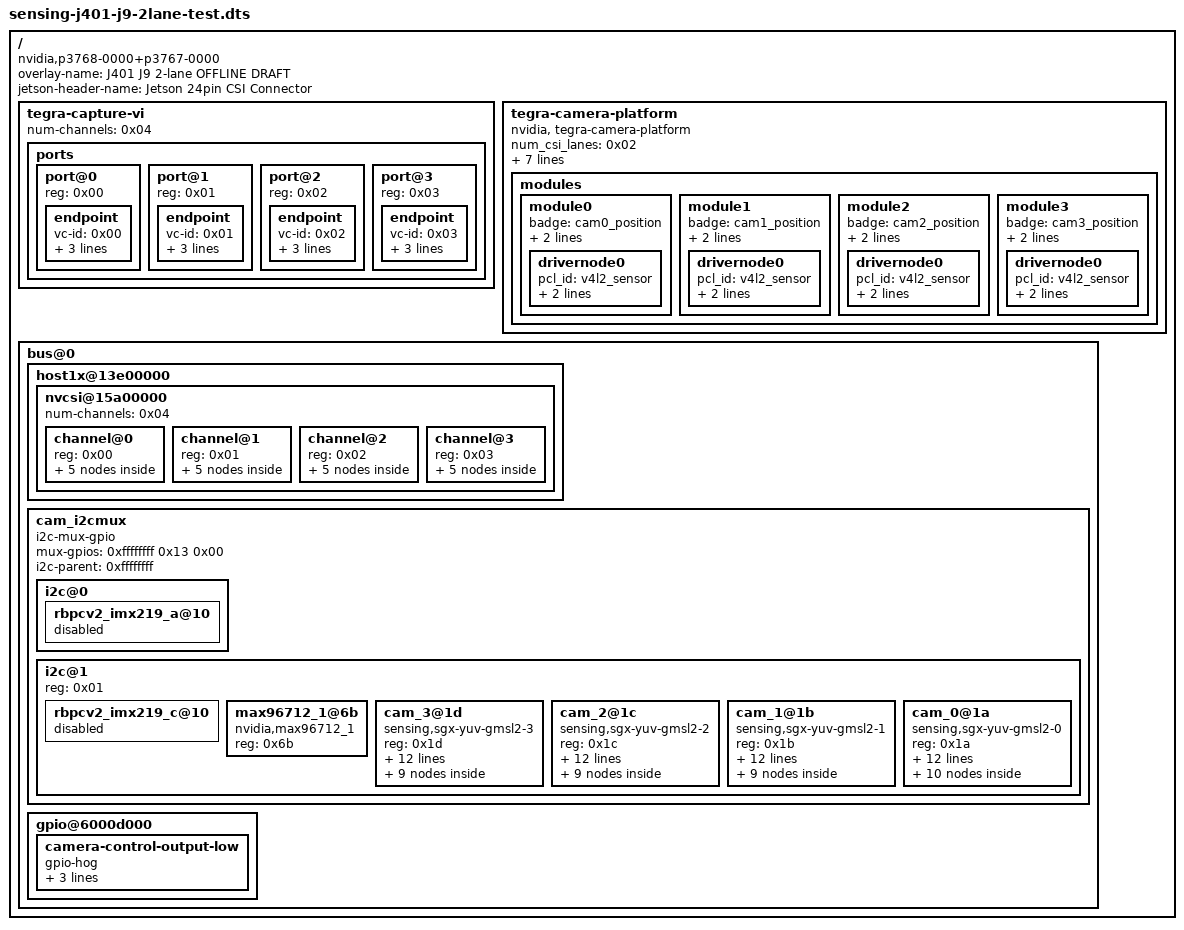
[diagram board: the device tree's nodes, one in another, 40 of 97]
/dts-v1/;

/ {
	overlay-name = "J401 J9 2-lane OFFLINE DRAFT";
	jetson-header-name = "Jetson 24pin CSI Connector";
	compatible = "nvidia,p3768-0000+p3767-0000\0nvidia,p3768-0000+p3767-0001\0nvidia,p3768-0000+p3767-0003\0nvidia,p3768-0000+p3767-0004\0nvidia,p3768-0000+p3767-0005\0nvidia,p3768-0000+p3767-0000-super\0nvidia,p3768-0000+p3767-0001-super\0nvidia,p3768-0000+p3767-0003-super\0nvidia,p3768-0000+p3767-0004-super\0nvidia,p3768-0000+p3767-0005-super";

	fragment@0 {
		target-path = "/";

		__overlay__ {

			tegra-capture-vi {
				num-channels = <0x04>;

				ports {
					#address-cells = <0x01>;
					#size-cells = <0x00>;

					port@0 {
						reg = <0x00>;

						endpoint {
							vc-id = <0x00>;
							port-index = <0x02>;
							bus-width = <0x02>;
							remote-endpoint = <0x01>;
							phandle = <0x06>;
						};
					};

					port@1 {
						reg = <0x01>;

						endpoint {
							vc-id = <0x01>;
							port-index = <0x02>;
							bus-width = <0x02>;
							remote-endpoint = <0x02>;
							phandle = <0x08>;
						};
					};

					port@2 {
						reg = <0x02>;

						endpoint {
							vc-id = <0x02>;
							port-index = <0x02>;
							bus-width = <0x02>;
							remote-endpoint = <0x03>;
							phandle = <0x0a>;
						};
					};

					port@3 {
						reg = <0x03>;

						endpoint {
							vc-id = <0x03>;
							port-index = <0x02>;
							bus-width = <0x02>;
							remote-endpoint = <0x04>;
							phandle = <0x0c>;
						};
					};
				};
			};

			tegra-camera-platform {
				compatible = "nvidia, tegra-camera-platform";
				num_csi_lanes = <0x02>;
				max_lane_speed = <0x16e360>;
				min_bits_per_pixel = <0x0a>;
				vi_peak_byte_per_pixel = <0x02>;
				vi_bw_margin_pct = <0x19>;
				max_pixel_rate = <0x7270e0>;
				isp_peak_byte_per_pixel = <0x05>;
				isp_bw_margin_pct = <0x19>;

				modules {

					module0 {
						badge = "cam0_position";
						position = "position";
						orientation = "1";

						drivernode0 {
							pcl_id = "v4l2_sensor";
							sysfs-device-tree = "/sys/firmware/devicetree/base/bus@0/cam_i2cmux/i2c@1/cam_0@1a";
						};
					};

					module1 {
						badge = "cam1_position";
						position = "position";
						orientation = "1";

						drivernode0 {
							pcl_id = "v4l2_sensor";
							sysfs-device-tree = "/sys/firmware/devicetree/base/bus@0/cam_i2cmux/i2c@1/cam_1@1b";
						};
					};

					module2 {
						badge = "cam2_position";
						position = "position";
						orientation = "1";

						drivernode0 {
							pcl_id = "v4l2_sensor";
							sysfs-device-tree = "/sys/firmware/devicetree/base/bus@0/cam_i2cmux/i2c@1/cam_2@1c";
						};
					};

					module3 {
						badge = "cam3_position";
						position = "position";
						orientation = "1";

						drivernode0 {
							pcl_id = "v4l2_sensor";
							sysfs-device-tree = "/sys/firmware/devicetree/base/bus@0/cam_i2cmux/i2c@1/cam_3@1d";
						};
					};
				};
			};

			bus@0 {

				host1x@13e00000 {

					nvcsi@15a00000 {
						num-channels = <0x04>;
						#address-cells = <0x01>;
						#size-cells = <0x00>;

						channel@0 {
							reg = <0x00>;

							ports {
								#address-cells = <0x01>;
								#size-cells = <0x00>;

								port@0 {
									reg = <0x00>;

									endpoint@0 {
										port-index = <0x02>;
										bus-width = <0x02>;
										remote-endpoint = <0x05>;
										phandle = <0x10>;
									};
								};

								port@1 {
									reg = <0x01>;

									endpoint@1 {
										remote-endpoint = <0x06>;
										phandle = <0x01>;
									};
								};
							};
						};

						channel@1 {
							reg = <0x01>;

							ports {
								#address-cells = <0x01>;
								#size-cells = <0x00>;

								port@0 {
									reg = <0x00>;

									endpoint@2 {
										port-index = <0x02>;
										bus-width = <0x02>;
										remote-endpoint = <0x07>;
										phandle = <0x0f>;
									};
								};

								port@1 {
									reg = <0x01>;

									endpoint@3 {
										remote-endpoint = <0x08>;
										phandle = <0x02>;
									};
								};
							};
						};

						channel@2 {
							reg = <0x02>;

							ports {
								#address-cells = <0x01>;
								#size-cells = <0x00>;

								port@0 {
									reg = <0x00>;

									endpoint@4 {
										port-index = <0x02>;
										bus-width = <0x02>;
										remote-endpoint = <0x09>;
										phandle = <0x0e>;
									};
								};

								port@1 {
									reg = <0x01>;

									endpoint@5 {
										remote-endpoint = <0x0a>;
										phandle = <0x03>;
									};
								};
							};
						};

						channel@3 {
							reg = <0x03>;

							ports {
								#address-cells = <0x01>;
								#size-cells = <0x00>;

								port@0 {
									reg = <0x00>;

									endpoint@6 {
										port-index = <0x02>;
										bus-width = <0x02>;
										remote-endpoint = <0x0b>;
										phandle = <0x0d>;
									};
								};

								port@1 {
									reg = <0x01>;

									endpoint@7 {
										remote-endpoint = <0x0c>;
										phandle = <0x04>;
									};
								};
							};
						};
					};
				};

				cam_i2cmux {
					status = "okay";
					compatible = "i2c-mux-gpio";
					#address-cells = <0x01>;
					#size-cells = <0x00>;
					mux-gpios = <0xffffffff 0x13 0x00>;
					i2c-parent = <0xffffffff>;

					i2c@0 {

						rbpcv2_imx219_a@10 {
							status = "disabled";
						};
					};

					i2c@1 {
						status = "okay";
						reg = <0x01>;
						#address-cells = <0x01>;
						#size-cells = <0x00>;

						rbpcv2_imx219_c@10 {
							status = "disabled";
						};

						max96712_1@6b {
							status = "okay";
							compatible = "nvidia,max96712_1";
							reg = <0x6b>;
						};

						cam_3@1d {
							status = "okay";
							compatible = "sensing,sgx-yuv-gmsl2-3";
							reg = <0x1d>;
							def_addr = <0x34>;
							devnode = "video3";
							physical_w = "15.0";
							physical_h = "12.5";
							sensor_model = "sgx-yuv-gmsl2";
							post_crop_frame_drop = "0";
							use_decibel_gain = "false";
							use_sensor_mode_id = "true";
							clocks = <0xffffffff 0x24 0xffffffff 0x24>;
							clock-names = "extperiph1\0pllp_grtba";
							mclk = "extperiph1";
							der_id = <0x01>;
							reset-gpios = <0xffffffff 0xa0 0x00>;

							mode0 {
								mclk_khz = "24000";
								num_lanes = "2";
								tegra_sinterface = "serial_c";
								vc_id = "3";
								discontinuous_clk = "no";
								dpcm_enable = "false";
								cil_settletime = "0";
								dynamic_pixel_bit_depth = "16";
								csi_pixel_bit_depth = "16";
								mode_type = "yuv";
								pixel_phase = "uyvy";
								active_w = "1920";
								active_h = "1080";
								readout_orientation = "0";
								line_length = "2200";
								inherent_gain = "1";
								pix_clk_hz = "150000000";
								serdes_pix_clk_hz = "350000000";
								gain_factor = "16";
								min_gain_val = "16";
								max_gain_val = "356";
								step_gain_val = "1";
								default_gain = "16";
								min_hdr_ratio = "1";
								max_hdr_ratio = "1";
								framerate_factor = "1000000";
								min_framerate = "30000000";
								max_framerate = "30000000";
								step_framerate = "1";
								default_framerate = "30000000";
								exposure_factor = "1000000";
								min_exp_time = "59";
								max_exp_time = "33333";
								step_exp_time = "1";
								default_exp_time = "33333";
								embedded_metadata_height = "0";
							};

							mode1 {
								mclk_khz = "24000";
								num_lanes = "2";
								tegra_sinterface = "serial_c";
								vc_id = "3";
								discontinuous_clk = "no";
								dpcm_enable = "false";
								cil_settletime = "0";
								dynamic_pixel_bit_depth = "16";
								csi_pixel_bit_depth = "16";
								mode_type = "yuv";
								pixel_phase = "uyvy";
								active_w = "1920";
								active_h = "1536";
								readout_orientation = "0";
								line_length = "2200";
								inherent_gain = "1";
								pix_clk_hz = "200000000";
								serdes_pix_clk_hz = "350000000";
								gain_factor = "16";
								min_gain_val = "16";
								max_gain_val = "356";
								step_gain_val = "1";
								default_gain = "16";
								min_hdr_ratio = "1";
								max_hdr_ratio = "1";
								framerate_factor = "1000000";
								min_framerate = "30000000";
								max_framerate = "30000000";
								step_framerate = "1";
								default_framerate = "30000000";
								exposure_factor = "1000000";
								min_exp_time = "28";
								max_exp_time = "22000";
								step_exp_time = "1";
								default_exp_time = "22000";
								embedded_metadata_height = "0";
							};

							mode2 {
								mclk_khz = "24000";
								num_lanes = "2";
								tegra_sinterface = "serial_c";
								vc_id = "3";
								discontinuous_clk = "no";
								dpcm_enable = "false";
								cil_settletime = "0";
								dynamic_pixel_bit_depth = "16";
								csi_pixel_bit_depth = "16";
								mode_type = "yuv";
								pixel_phase = "uyvy";
								active_w = "2880";
								active_h = "1860";
								readout_orientation = "0";
								line_length = "3200";
								inherent_gain = "1";
								pix_clk_hz = "214300000";
								serdes_pix_clk_hz = "350000000";
								gain_factor = "16";
								min_gain_val = "16";
								max_gain_val = "356";
								step_gain_val = "1";
								default_gain = "16";
								min_hdr_ratio = "1";
								max_hdr_ratio = "1";
								framerate_factor = "1000000";
								min_framerate = "30000000";
								max_framerate = "30000000";
								step_framerate = "1";
								default_framerate = "30000000";
								exposure_factor = "1000000";
								min_exp_time = "59";
								max_exp_time = "33333";
								step_exp_time = "1";
								default_exp_time = "33333";
								embedded_metadata_height = "0";
							};

							mode3 {
								mclk_khz = "24000";
								num_lanes = "2";
								tegra_sinterface = "serial_c";
								vc_id = "3";
								discontinuous_clk = "no";
								dpcm_enable = "false";
								cil_settletime = "0";
								dynamic_pixel_bit_depth = "16";
								csi_pixel_bit_depth = "16";
								mode_type = "yuv";
								pixel_phase = "uyvy";
								active_w = "3840";
								active_h = "2160";
								readout_orientation = "0";
								line_length = "4200";
								inherent_gain = "1";
								pix_clk_hz = "150000000";
								serdes_pix_clk_hz = "350000000";
								gain_factor = "16";
								min_gain_val = "16";
								max_gain_val = "356";
								step_gain_val = "1";
								default_gain = "16";
								min_hdr_ratio = "1";
								max_hdr_ratio = "1";
								framerate_factor = "1000000";
								min_framerate = "30000000";
								max_framerate = "30000000";
								step_framerate = "1";
								default_framerate = "30000000";
								exposure_factor = "1000000";
								min_exp_time = "59";
								max_exp_time = "33333";
								step_exp_time = "1";
								default_exp_time = "33333";
								embedded_metadata_height = "0";
							};

							mode4 {
								mclk_khz = "24000";
								num_lanes = "2";
								tegra_sinterface = "serial_c";
								vc_id = "3";
								discontinuous_clk = "no";
								dpcm_enable = "false";
								cil_settletime = "0";
								dynamic_pixel_bit_depth = "16";
								csi_pixel_bit_depth = "16";
								mode_type = "yuv";
								pixel_phase = "uyvy";
								active_w = "1280";
								active_h = "720";
								readout_orientation = "0";
								line_length = "2200";
								inherent_gain = "1";
								pix_clk_hz = "150000000";
								serdes_pix_clk_hz = "350000000";
								gain_factor = "16";
								min_gain_val = "16";
								max_gain_val = "356";
								step_gain_val = "1";
								default_gain = "16";
								min_hdr_ratio = "1";
								max_hdr_ratio = "1";
								framerate_factor = "1000000";
								min_framerate = "30000000";
								max_framerate = "30000000";
								step_framerate = "1";
								default_framerate = "30000000";
								exposure_factor = "1000000";
								min_exp_time = "59";
								max_exp_time = "33333";
								step_exp_time = "1";
								default_exp_time = "33333";
								embedded_metadata_height = "0";
							};

							mode5 {
								mclk_khz = "24000";
								num_lanes = "2";
								tegra_sinterface = "serial_c";
								vc_id = "3";
								discontinuous_clk = "no";
								dpcm_enable = "false";
								cil_settletime = "0";
								dynamic_pixel_bit_depth = "16";
								csi_pixel_bit_depth = "16";
								mode_type = "yuv";
								pixel_phase = "uyvy";
								active_w = "3840";
								active_h = "2160";
								readout_orientation = "0";
								line_length = "2200";
								inherent_gain = "1";
								pix_clk_hz = "150000000";
								serdes_pix_clk_hz = "350000000";
								gain_factor = "16";
								min_gain_val = "16";
								max_gain_val = "356";
								step_gain_val = "1";
								default_gain = "16";
								min_hdr_ratio = "1";
								max_hdr_ratio = "1";
								framerate_factor = "1000000";
								min_framerate = "30000000";
								max_framerate = "30000000";
								step_framerate = "1";
								default_framerate = "30000000";
								exposure_factor = "1000000";
								min_exp_time = "59";
								max_exp_time = "33333";
								step_exp_time = "1";
								default_exp_time = "33333";
								embedded_metadata_height = "0";
							};

							ports {
								#address-cells = <0x01>;
								#size-cells = <0x00>;

								port@0 {
									reg = <0x00>;

									endpoint {
										vc-id = <0x03>;
										port-index = <0x02>;
										bus-width = <0x02>;
										remote-endpoint = <0x0d>;
										phandle = <0x0b>;
									};
								};
							};
						};

						cam_2@1c {
							status = "okay";
							compatible = "sensing,sgx-yuv-gmsl2-2";
							reg = <0x1c>;
							def_addr = <0x34>;
							devnode = "video2";
							physical_w = "15.0";
							physical_h = "12.5";
							sensor_model = "sgx-yuv-gmsl2";
							post_crop_frame_drop = "0";
							use_decibel_gain = "false";
							use_sensor_mode_id = "true";
							clocks = <0xffffffff 0x24 0xffffffff 0x24>;
							clock-names = "extperiph1\0pllp_grtba";
							mclk = "extperiph1";
							der_id = <0x01>;
							reset-gpios = <0xffffffff 0xa0 0x00>;

							mode0 {
								mclk_khz = "24000";
								num_lanes = "2";
								tegra_sinterface = "serial_c";
								vc_id = "2";
								discontinuous_clk = "no";
								dpcm_enable = "false";
								cil_settletime = "0";
								dynamic_pixel_bit_depth = "16";
								csi_pixel_bit_depth = "16";
								mode_type = "yuv";
								pixel_phase = "uyvy";
								active_w = "1920";
								active_h = "1080";
								readout_orientation = "0";
								line_length = "2200";
								inherent_gain = "1";
								pix_clk_hz = "150000000";
								serdes_pix_clk_hz = "350000000";
								gain_factor = "16";
								min_gain_val = "16";
								max_gain_val = "356";
								step_gain_val = "1";
								default_gain = "16";
								min_hdr_ratio = "1";
								max_hdr_ratio = "1";
								framerate_factor = "1000000";
								min_framerate = "30000000";
								max_framerate = "30000000";
								step_framerate = "1";
								default_framerate = "30000000";
								exposure_factor = "1000000";
								min_exp_time = "59";
								max_exp_time = "33333";
								step_exp_time = "1";
								default_exp_time = "33333";
								embedded_metadata_height = "0";
							};

							mode1 {
								mclk_khz = "24000";
								num_lanes = "2";
								tegra_sinterface = "serial_c";
								vc_id = "2";
								discontinuous_clk = "no";
								dpcm_enable = "false";
								cil_settletime = "0";
								dynamic_pixel_bit_depth = "16";
								csi_pixel_bit_depth = "16";
								mode_type = "yuv";
								pixel_phase = "uyvy";
								active_w = "1920";
								active_h = "1536";
								readout_orientation = "0";
								line_length = "2200";
								inherent_gain = "1";
								pix_clk_hz = "200000000";
								serdes_pix_clk_hz = "350000000";
								gain_factor = "16";
								min_gain_val = "16";
								max_gain_val = "356";
								step_gain_val = "1";
								default_gain = "16";
								min_hdr_ratio = "1";
								max_hdr_ratio = "1";
								framerate_factor = "1000000";
								min_framerate = "30000000";
								max_framerate = "30000000";
								step_framerate = "1";
								default_framerate = "30000000";
								exposure_factor = "1000000";
								min_exp_time = "28";
								max_exp_time = "22000";
								step_exp_time = "1";
								default_exp_time = "22000";
								embedded_metadata_height = "0";
							};

							mode2 {
								mclk_khz = "24000";
								num_lanes = "2";
								tegra_sinterface = "serial_c";
								vc_id = "2";
								discontinuous_clk = "no";
								dpcm_enable = "false";
								cil_settletime = "0";
								dynamic_pixel_bit_depth = "16";
								csi_pixel_bit_depth = "16";
								mode_type = "yuv";
								pixel_phase = "uyvy";
								active_w = "2880";
								active_h = "1860";
								readout_orientation = "0";
								line_length = "3200";
								inherent_gain = "1";
								pix_clk_hz = "214300000";
								serdes_pix_clk_hz = "350000000";
								gain_factor = "16";
								min_gain_val = "16";
								max_gain_val = "356";
								step_gain_val = "1";
								default_gain = "16";
								min_hdr_ratio = "1";
								max_hdr_ratio = "1";
								framerate_factor = "1000000";
								min_framerate = "30000000";
								max_framerate = "30000000";
								step_framerate = "1";
								default_framerate = "30000000";
								exposure_factor = "1000000";
								min_exp_time = "59";
								max_exp_time = "33333";
								step_exp_time = "1";
								default_exp_time = "33333";
								embedded_metadata_height = "0";
							};

							mode3 {
								mclk_khz = "24000";
								num_lanes = "2";
								tegra_sinterface = "serial_c";
								vc_id = "2";
								discontinuous_clk = "no";
								dpcm_enable = "false";
								cil_settletime = "0";
								dynamic_pixel_bit_depth = "16";
								csi_pixel_bit_depth = "16";
								mode_type = "yuv";
								pixel_phase = "uyvy";
								active_w = "3840";
								active_h = "2160";
								readout_orientation = "0";
								line_length = "4200";
								inherent_gain = "1";
								pix_clk_hz = "150000000";
								serdes_pix_clk_hz = "350000000";
								gain_factor = "16";
								min_gain_val = "16";
								max_gain_val = "356";
								step_gain_val = "1";
								default_gain = "16";
								min_hdr_ratio = "1";
								max_hdr_ratio = "1";
								framerate_factor = "1000000";
								min_framerate = "30000000";
								max_framerate = "30000000";
								step_framerate = "1";
								default_framerate = "30000000";
								exposure_factor = "1000000";
								min_exp_time = "59";
								max_exp_time = "33333";
								step_exp_time = "1";
								default_exp_time = "33333";
								embedded_metadata_height = "0";
							};

							mode4 {
								mclk_khz = "24000";
								num_lanes = "2";
								tegra_sinterface = "serial_c";
								vc_id = "2";
								discontinuous_clk = "no";
								dpcm_enable = "false";
								cil_settletime = "0";
								dynamic_pixel_bit_depth = "16";
								csi_pixel_bit_depth = "16";
								mode_type = "yuv";
								pixel_phase = "uyvy";
								active_w = "1280";
								active_h = "720";
								readout_orientation = "0";
								line_length = "2200";
								inherent_gain = "1";
								pix_clk_hz = "150000000";
								serdes_pix_clk_hz = "350000000";
								gain_factor = "16";
								min_gain_val = "16";
								max_gain_val = "356";
								step_gain_val = "1";
								default_gain = "16";
								min_hdr_ratio = "1";
								max_hdr_ratio = "1";
								framerate_factor = "1000000";
								min_framerate = "30000000";
								max_framerate = "30000000";
								step_framerate = "1";
								default_framerate = "30000000";
								exposure_factor = "1000000";
								min_exp_time = "59";
								max_exp_time = "33333";
								step_exp_time = "1";
								default_exp_time = "33333";
								embedded_metadata_height = "0";
							};

							mode5 {
								mclk_khz = "24000";
								num_lanes = "2";
								tegra_sinterface = "serial_c";
								vc_id = "2";
								discontinuous_clk = "no";
								dpcm_enable = "false";
								cil_settletime = "0";
								dynamic_pixel_bit_depth = "16";
								csi_pixel_bit_depth = "16";
								mode_type = "yuv";
								pixel_phase = "uyvy";
								active_w = "3840";
								active_h = "2160";
								readout_orientation = "0";
								line_length = "2200";
								inherent_gain = "1";
								pix_clk_hz = "150000000";
								serdes_pix_clk_hz = "350000000";
								gain_factor = "16";
								min_gain_val = "16";
								max_gain_val = "356";
								step_gain_val = "1";
								default_gain = "16";
								min_hdr_ratio = "1";
								max_hdr_ratio = "1";
								framerate_factor = "1000000";
								min_framerate = "30000000";
								max_framerate = "30000000";
								step_framerate = "1";
								default_framerate = "30000000";
								exposure_factor = "1000000";
								min_exp_time = "59";
								max_exp_time = "33333";
								step_exp_time = "1";
								default_exp_time = "33333";
								embedded_metadata_height = "0";
							};

							ports {
								#address-cells = <0x01>;
								#size-cells = <0x00>;

								port@0 {
									reg = <0x00>;

									endpoint {
										vc-id = <0x02>;
										port-index = <0x02>;
										bus-width = <0x02>;
										remote-endpoint = <0x0e>;
										phandle = <0x09>;
									};
								};
							};
						};

						cam_1@1b {
							status = "okay";
							compatible = "sensing,sgx-yuv-gmsl2-1";
							reg = <0x1b>;
							def_addr = <0x34>;
							devnode = "video1";
							physical_w = "15.0";
							physical_h = "12.5";
							sensor_model = "sgx-yuv-gmsl2";
							post_crop_frame_drop = "0";
							use_decibel_gain = "false";
							use_sensor_mode_id = "true";
							clocks = <0xffffffff 0x24 0xffffffff 0x24>;
							clock-names = "extperiph1\0pllp_grtba";
							mclk = "extperiph1";
							der_id = <0x01>;
							reset-gpios = <0xffffffff 0xa0 0x00>;

							mode0 {
								mclk_khz = "24000";
								num_lanes = "2";
								tegra_sinterface = "serial_c";
								vc_id = "1";
								discontinuous_clk = "no";
								dpcm_enable = "false";
								cil_settletime = "0";
								dynamic_pixel_bit_depth = "16";
								csi_pixel_bit_depth = "16";
								mode_type = "yuv";
								pixel_phase = "uyvy";
								active_w = "1920";
								active_h = "1080";
								readout_orientation = "0";
								line_length = "2200";
								inherent_gain = "1";
								pix_clk_hz = "150000000";
								serdes_pix_clk_hz = "350000000";
								gain_factor = "16";
								min_gain_val = "16";
								max_gain_val = "356";
								step_gain_val = "1";
								default_gain = "16";
								min_hdr_ratio = "1";
								max_hdr_ratio = "1";
								framerate_factor = "1000000";
								min_framerate = "30000000";
								max_framerate = "30000000";
								step_framerate = "1";
								default_framerate = "30000000";
								exposure_factor = "1000000";
								min_exp_time = "59";
								max_exp_time = "33333";
								step_exp_time = "1";
								default_exp_time = "33333";
								embedded_metadata_height = "0";
							};

							mode1 {
								mclk_khz = "24000";
								num_lanes = "2";
								tegra_sinterface = "serial_c";
								vc_id = "1";
								discontinuous_clk = "no";
								dpcm_enable = "false";
								cil_settletime = "0";
								dynamic_pixel_bit_depth = "16";
								csi_pixel_bit_depth = "16";
								mode_type = "yuv";
								pixel_phase = "uyvy";
								active_w = "1920";
								active_h = "1536";
								readout_orientation = "0";
								line_length = "2200";
								inherent_gain = "1";
								pix_clk_hz = "200000000";
								serdes_pix_clk_hz = "350000000";
								gain_factor = "16";
								min_gain_val = "16";
								max_gain_val = "356";
								step_gain_val = "1";
								default_gain = "16";
								min_hdr_ratio = "1";
								max_hdr_ratio = "1";
								framerate_factor = "1000000";
								min_framerate = "30000000";
								max_framerate = "30000000";
								step_framerate = "1";
								default_framerate = "30000000";
								exposure_factor = "1000000";
								min_exp_time = "28";
								max_exp_time = "22000";
								step_exp_time = "1";
								default_exp_time = "22000";
								embedded_metadata_height = "0";
							};

							mode2 {
								mclk_khz = "24000";
								num_lanes = "2";
								tegra_sinterface = "serial_c";
								vc_id = "1";
								discontinuous_clk = "no";
								dpcm_enable = "false";
								cil_settletime = "0";
								dynamic_pixel_bit_depth = "16";
								csi_pixel_bit_depth = "16";
								mode_type = "yuv";
								pixel_phase = "uyvy";
								active_w = "2880";
								active_h = "1860";
								readout_orientation = "0";
								line_length = "3200";
								inherent_gain = "1";
								pix_clk_hz = "214300000";
								serdes_pix_clk_hz = "350000000";
								gain_factor = "16";
								min_gain_val = "16";
								max_gain_val = "356";
								step_gain_val = "1";
								default_gain = "16";
								min_hdr_ratio = "1";
								max_hdr_ratio = "1";
								framerate_factor = "1000000";
								min_framerate = "30000000";
								max_framerate = "30000000";
								step_framerate = "1";
								default_framerate = "30000000";
								exposure_factor = "1000000";
								min_exp_time = "59";
								max_exp_time = "33333";
								step_exp_time = "1";
								default_exp_time = "33333";
								embedded_metadata_height = "0";
							};

							mode3 {
								mclk_khz = "24000";
								num_lanes = "2";
								tegra_sinterface = "serial_c";
								vc_id = "1";
								discontinuous_clk = "no";
								dpcm_enable = "false";
								cil_settletime = "0";
								dynamic_pixel_bit_depth = "16";
								csi_pixel_bit_depth = "16";
								mode_type = "yuv";
								pixel_phase = "uyvy";
								active_w = "3840";
								active_h = "2160";
								readout_orientation = "0";
								line_length = "4200";
								inherent_gain = "1";
								pix_clk_hz = "150000000";
								serdes_pix_clk_hz = "350000000";
								gain_factor = "16";
								min_gain_val = "16";
								max_gain_val = "356";
								step_gain_val = "1";
								default_gain = "16";
								min_hdr_ratio = "1";
								max_hdr_ratio = "1";
								framerate_factor = "1000000";
								min_framerate = "30000000";
								max_framerate = "30000000";
								step_framerate = "1";
								default_framerate = "30000000";
								exposure_factor = "1000000";
								min_exp_time = "59";
								max_exp_time = "33333";
								step_exp_time = "1";
								default_exp_time = "33333";
								embedded_metadata_height = "0";
							};

							mode4 {
								mclk_khz = "24000";
								num_lanes = "2";
								tegra_sinterface = "serial_c";
								vc_id = "1";
								discontinuous_clk = "no";
								dpcm_enable = "false";
								cil_settletime = "0";
								dynamic_pixel_bit_depth = "16";
								csi_pixel_bit_depth = "16";
								mode_type = "yuv";
								pixel_phase = "uyvy";
								active_w = "1280";
								active_h = "720";
								readout_orientation = "0";
								line_length = "2200";
								inherent_gain = "1";
								pix_clk_hz = "150000000";
								serdes_pix_clk_hz = "350000000";
								gain_factor = "16";
								min_gain_val = "16";
								max_gain_val = "356";
								step_gain_val = "1";
								default_gain = "16";
								min_hdr_ratio = "1";
								max_hdr_ratio = "1";
								framerate_factor = "1000000";
								min_framerate = "30000000";
								max_framerate = "30000000";
								step_framerate = "1";
								default_framerate = "30000000";
								exposure_factor = "1000000";
								min_exp_time = "59";
								max_exp_time = "33333";
								step_exp_time = "1";
								default_exp_time = "33333";
								embedded_metadata_height = "0";
							};

							mode5 {
								mclk_khz = "24000";
								num_lanes = "2";
								tegra_sinterface = "serial_c";
								vc_id = "1";
								discontinuous_clk = "no";
								dpcm_enable = "false";
								cil_settletime = "0";
								dynamic_pixel_bit_depth = "16";
								csi_pixel_bit_depth = "16";
								mode_type = "yuv";
								pixel_phase = "uyvy";
								active_w = "3840";
								active_h = "2160";
								readout_orientation = "0";
								line_length = "2200";
								inherent_gain = "1";
								pix_clk_hz = "150000000";
								serdes_pix_clk_hz = "350000000";
								gain_factor = "16";
								min_gain_val = "16";
								max_gain_val = "356";
								step_gain_val = "1";
								default_gain = "16";
								min_hdr_ratio = "1";
								max_hdr_ratio = "1";
								framerate_factor = "1000000";
								min_framerate = "30000000";
								max_framerate = "30000000";
								step_framerate = "1";
								default_framerate = "30000000";
								exposure_factor = "1000000";
								min_exp_time = "59";
								max_exp_time = "33333";
								step_exp_time = "1";
								default_exp_time = "33333";
								embedded_metadata_height = "0";
							};

							ports {
								#address-cells = <0x01>;
								#size-cells = <0x00>;

								port@0 {
									reg = <0x00>;

									endpoint {
										vc-id = <0x01>;
										port-index = <0x02>;
										bus-width = <0x02>;
										remote-endpoint = <0x0f>;
										phandle = <0x07>;
									};
								};
							};
						};

						cam_0@1a {
							status = "okay";
							compatible = "sensing,sgx-yuv-gmsl2-0";
							reg = <0x1a>;
							def_addr = <0x34>;
							devnode = "video0";
							physical_w = "15.0";
							physical_h = "12.5";
							sensor_model = "sgx-yuv-gmsl2";
							post_crop_frame_drop = "0";
							use_decibel_gain = "false";
							use_sensor_mode_id = "true";
							clocks = <0xffffffff 0x24 0xffffffff 0x24>;
							clock-names = "extperiph1\0pllp_grtba";
							mclk = "extperiph1";
							der_id = <0x01>;
							reset-gpios = <0xffffffff 0xa0 0x00>;

							mode0 {
								mclk_khz = "24000";
								num_lanes = "2";
								tegra_sinterface = "serial_c";
								vc_id = "0";
								discontinuous_clk = "no";
								dpcm_enable = "false";
								cil_settletime = "0";
								dynamic_pixel_bit_depth = "16";
								csi_pixel_bit_depth = "16";
								mode_type = "yuv";
								pixel_phase = "uyvy";
								active_w = "1920";
								active_h = "1080";
								readout_orientation = "0";
								line_length = "2200";
								inherent_gain = "1";
								pix_clk_hz = "150000000";
								serdes_pix_clk_hz = "350000000";
								gain_factor = "16";
								min_gain_val = "16";
								max_gain_val = "356";
								step_gain_val = "1";
								default_gain = "16";
								min_hdr_ratio = "1";
								max_hdr_ratio = "1";
								framerate_factor = "1000000";
								min_framerate = "30000000";
								max_framerate = "30000000";
								step_framerate = "1";
								default_framerate = "30000000";
								exposure_factor = "1000000";
								min_exp_time = "59";
								max_exp_time = "33333";
								step_exp_time = "1";
								default_exp_time = "33333";
								embedded_metadata_height = "0";
							};

							mode1 {
								mclk_khz = "24000";
								num_lanes = "2";
								tegra_sinterface = "serial_c";
								vc_id = "0";
								discontinuous_clk = "no";
								dpcm_enable = "false";
								cil_settletime = "0";
								dynamic_pixel_bit_depth = "16";
								csi_pixel_bit_depth = "16";
								mode_type = "yuv";
								pixel_phase = "uyvy";
								active_w = "1920";
								active_h = "1536";
								readout_orientation = "0";
								line_length = "2200";
								inherent_gain = "1";
								pix_clk_hz = "200000000";
								serdes_pix_clk_hz = "350000000";
								gain_factor = "16";
								min_gain_val = "16";
								max_gain_val = "356";
								step_gain_val = "1";
								default_gain = "16";
								min_hdr_ratio = "1";
								max_hdr_ratio = "1";
								framerate_factor = "1000000";
								min_framerate = "30000000";
								max_framerate = "30000000";
								step_framerate = "1";
								default_framerate = "30000000";
								exposure_factor = "1000000";
								min_exp_time = "28";
								max_exp_time = "22000";
								step_exp_time = "1";
								default_exp_time = "22000";
								embedded_metadata_height = "0";
							};

							mode2 {
								mclk_khz = "24000";
								num_lanes = "2";
								tegra_sinterface = "serial_c";
								vc_id = "0";
								discontinuous_clk = "no";
								dpcm_enable = "false";
								cil_settletime = "0";
								dynamic_pixel_bit_depth = "16";
								csi_pixel_bit_depth = "16";
								mode_type = "yuv";
								pixel_phase = "uyvy";
								active_w = "2880";
								active_h = "1860";
								readout_orientation = "0";
								line_length = "3200";
								inherent_gain = "1";
								pix_clk_hz = "214300000";
								serdes_pix_clk_hz = "350000000";
								gain_factor = "16";
								min_gain_val = "16";
								max_gain_val = "356";
								step_gain_val = "1";
								default_gain = "16";
								min_hdr_ratio = "1";
								max_hdr_ratio = "1";
								framerate_factor = "1000000";
								min_framerate = "30000000";
								max_framerate = "30000000";
								step_framerate = "1";
								default_framerate = "30000000";
								exposure_factor = "1000000";
								min_exp_time = "59";
								max_exp_time = "33333";
								step_exp_time = "1";
								default_exp_time = "33333";
								embedded_metadata_height = "0";
							};

							mode3 {
								mclk_khz = "24000";
								num_lanes = "2";
								tegra_sinterface = "serial_c";
								vc_id = "0";
								discontinuous_clk = "no";
								dpcm_enable = "false";
								cil_settletime = "0";
								dynamic_pixel_bit_depth = "16";
								csi_pixel_bit_depth = "16";
								mode_type = "yuv";
								pixel_phase = "uyvy";
								active_w = "3840";
								active_h = "2160";
								readout_orientation = "0";
								line_length = "4200";
								inherent_gain = "1";
								pix_clk_hz = "150000000";
								serdes_pix_clk_hz = "350000000";
								gain_factor = "16";
								min_gain_val = "16";
								max_gain_val = "356";
								step_gain_val = "1";
								default_gain = "16";
								min_hdr_ratio = "1";
								max_hdr_ratio = "1";
								framerate_factor = "1000000";
								min_framerate = "30000000";
								max_framerate = "30000000";
								step_framerate = "1";
								default_framerate = "30000000";
								exposure_factor = "1000000";
								min_exp_time = "59";
								max_exp_time = "33333";
								step_exp_time = "1";
								default_exp_time = "33333";
								embedded_metadata_height = "0";
							};

							mode4 {
								mclk_khz = "24000";
								num_lanes = "2";
								tegra_sinterface = "serial_c";
								vc_id = "0";
								discontinuous_clk = "no";
								dpcm_enable = "false";
								cil_settletime = "0";
								dynamic_pixel_bit_depth = "16";
								csi_pixel_bit_depth = "16";
								mode_type = "yuv";
								pixel_phase = "uyvy";
								active_w = "1280";
								active_h = "720";
								readout_orientation = "0";
								line_length = "2200";
								inherent_gain = "1";
								pix_clk_hz = "150000000";
								serdes_pix_clk_hz = "350000000";
								gain_factor = "16";
								min_gain_val = "16";
								max_gain_val = "356";
								step_gain_val = "1";
								default_gain = "16";
								min_hdr_ratio = "1";
								max_hdr_ratio = "1";
								framerate_factor = "1000000";
								min_framerate = "30000000";
								max_framerate = "30000000";
								step_framerate = "1";
								default_framerate = "30000000";
								exposure_factor = "1000000";
								min_exp_time = "59";
								max_exp_time = "33333";
								step_exp_time = "1";
								default_exp_time = "33333";
								embedded_metadata_height = "0";
							};

							mode5 {
								mclk_khz = "24000";
								num_lanes = "2";
								tegra_sinterface = "serial_c";
								vc_id = "0";
								discontinuous_clk = "no";
								dpcm_enable = "false";
								cil_settletime = "0";
								dynamic_pixel_bit_depth = "16";
								csi_pixel_bit_depth = "16";
								mode_type = "yuv";
								pixel_phase = "uyvy";
								active_w = "3840";
								active_h = "2160";
								readout_orientation = "0";
								line_length = "2200";
								inherent_gain = "1";
								pix_clk_hz = "150000000";
								serdes_pix_clk_hz = "350000000";
								gain_factor = "16";
								min_gain_val = "16";
								max_gain_val = "356";
								step_gain_val = "1";
								default_gain = "16";
								min_hdr_ratio = "1";
								max_hdr_ratio = "1";
								framerate_factor = "1000000";
								min_framerate = "30000000";
								max_framerate = "30000000";
								step_framerate = "1";
								default_framerate = "30000000";
								exposure_factor = "1000000";
								min_exp_time = "59";
								max_exp_time = "33333";
								step_exp_time = "1";
								default_exp_time = "33333";
								embedded_metadata_height = "0";
							};

							ports {
								#address-cells = <0x01>;
								#size-cells = <0x00>;

								port@0 {
									reg = <0x00>;

									endpoint {
										vc-id = <0x00>;
										port-index = <0x02>;
										bus-width = <0x02>;
										remote-endpoint = <0x10>;
										phandle = <0x05>;
									};
								};
							};

							gmsl-link {
								src-csi-port = "b";
								dst-csi-port = "a";
								serdes-csi-link = "a";
								csi-mode = "1x4";
								st-vc = <0x00>;
								vc-id = <0x00>;
								num-lanes = <0x04>;
								streams = "ued-u1\0yuv16";
							};
						};
					};
				};

				gpio@6000d000 {

					camera-control-output-low {
						gpio-hog;
						output-low;
						gpios = <0xa0 0x00 0x3e 0x00>;
						label = "cam1-pwdn\0cam0-pwdn";
					};
				};
			};
		};
	};

	__symbols__ {
		jetson_vi_in0 = "/fragment@0/__overlay__/tegra-capture-vi/ports/port@0/endpoint";
		jetson_vi_in1 = "/fragment@0/__overlay__/tegra-capture-vi/ports/port@1/endpoint";
		jetson_vi_in2 = "/fragment@0/__overlay__/tegra-capture-vi/ports/port@2/endpoint";
		jetson_vi_in3 = "/fragment@0/__overlay__/tegra-capture-vi/ports/port@3/endpoint";
		jetson_csi_in0 = "/fragment@0/__overlay__/bus@0/host1x@13e00000/nvcsi@15a00000/channel@0/ports/port@0/endpoint@0";
		jetson_csi_out0 = "/fragment@0/__overlay__/bus@0/host1x@13e00000/nvcsi@15a00000/channel@0/ports/port@1/endpoint@1";
		jetson_csi_in1 = "/fragment@0/__overlay__/bus@0/host1x@13e00000/nvcsi@15a00000/channel@1/ports/port@0/endpoint@2";
		jetson_csi_out1 = "/fragment@0/__overlay__/bus@0/host1x@13e00000/nvcsi@15a00000/channel@1/ports/port@1/endpoint@3";
		jetson_csi_in2 = "/fragment@0/__overlay__/bus@0/host1x@13e00000/nvcsi@15a00000/channel@2/ports/port@0/endpoint@4";
		jetson_csi_out2 = "/fragment@0/__overlay__/bus@0/host1x@13e00000/nvcsi@15a00000/channel@2/ports/port@1/endpoint@5";
		jetson_csi_in3 = "/fragment@0/__overlay__/bus@0/host1x@13e00000/nvcsi@15a00000/channel@3/ports/port@0/endpoint@6";
		jetson_csi_out3 = "/fragment@0/__overlay__/bus@0/host1x@13e00000/nvcsi@15a00000/channel@3/ports/port@1/endpoint@7";
		mipi_cam_out3 = "/fragment@0/__overlay__/bus@0/cam_i2cmux/i2c@1/cam_3@1d/ports/port@0/endpoint";
		mipi_cam_out2 = "/fragment@0/__overlay__/bus@0/cam_i2cmux/i2c@1/cam_2@1c/ports/port@0/endpoint";
		mipi_cam_out1 = "/fragment@0/__overlay__/bus@0/cam_i2cmux/i2c@1/cam_1@1b/ports/port@0/endpoint";
		mipi_cam_out0 = "/fragment@0/__overlay__/bus@0/cam_i2cmux/i2c@1/cam_0@1a/ports/port@0/endpoint";
	};

	__fixups__ {
		gpio_aon = "/fragment@0/__overlay__/bus@0/cam_i2cmux:mux-gpios:0";
		cam_i2c = "/fragment@0/__overlay__/bus@0/cam_i2cmux:i2c-parent:0";
		bpmp = "/fragment@0/__overlay__/bus@0/cam_i2cmux/i2c@1/cam_3@1d:clocks:0\0/fragment@0/__overlay__/bus@0/cam_i2cmux/i2c@1/cam_3@1d:clocks:8\0/fragment@0/__overlay__/bus@0/cam_i2cmux/i2c@1/cam_2@1c:clocks:0\0/fragment@0/__overlay__/bus@0/cam_i2cmux/i2c@1/cam_2@1c:clocks:8\0/fragment@0/__overlay__/bus@0/cam_i2cmux/i2c@1/cam_1@1b:clocks:0\0/fragment@0/__overlay__/bus@0/cam_i2cmux/i2c@1/cam_1@1b:clocks:8\0/fragment@0/__overlay__/bus@0/cam_i2cmux/i2c@1/cam_0@1a:clocks:0\0/fragment@0/__overlay__/bus@0/cam_i2cmux/i2c@1/cam_0@1a:clocks:8";
		gpio = "/fragment@0/__overlay__/bus@0/cam_i2cmux/i2c@1/cam_3@1d:reset-gpios:0\0/fragment@0/__overlay__/bus@0/cam_i2cmux/i2c@1/cam_2@1c:reset-gpios:0\0/fragment@0/__overlay__/bus@0/cam_i2cmux/i2c@1/cam_1@1b:reset-gpios:0\0/fragment@0/__overlay__/bus@0/cam_i2cmux/i2c@1/cam_0@1a:reset-gpios:0";
	};

	__local_fixups__ {

		fragment@0 {

			__overlay__ {

				tegra-capture-vi {

					ports {

						port@0 {

							endpoint {
								remote-endpoint = <0x00>;
							};
						};

						port@1 {

							endpoint {
								remote-endpoint = <0x00>;
							};
						};

						port@2 {

							endpoint {
								remote-endpoint = <0x00>;
							};
						};

						port@3 {

							endpoint {
								remote-endpoint = <0x00>;
							};
						};
					};
				};

				bus@0 {

					host1x@13e00000 {

						nvcsi@15a00000 {

							channel@0 {

								ports {

									port@0 {

										endpoint@0 {
											remote-endpoint = <0x00>;
										};
									};

									port@1 {

										endpoint@1 {
											remote-endpoint = <0x00>;
										};
									};
								};
							};

							channel@1 {

								ports {

									port@0 {

										endpoint@2 {
											remote-endpoint = <0x00>;
										};
									};

									port@1 {

										endpoint@3 {
											remote-endpoint = <0x00>;
										};
									};
								};
							};

							channel@2 {

								ports {

									port@0 {

										endpoint@4 {
											remote-endpoint = <0x00>;
										};
									};

									port@1 {

										endpoint@5 {
											remote-endpoint = <0x00>;
										};
									};
								};
							};

							channel@3 {

								ports {

									port@0 {

										endpoint@6 {
											remote-endpoint = <0x00>;
										};
									};

									port@1 {

										endpoint@7 {
											remote-endpoint = <0x00>;
										};
									};
								};
							};
						};
					};

					cam_i2cmux {

						i2c@1 {

							cam_3@1d {

								ports {

									port@0 {

										endpoint {
											remote-endpoint = <0x00>;
										};
									};
								};
							};

							cam_2@1c {

								ports {

									port@0 {

										endpoint {
											remote-endpoint = <0x00>;
										};
									};
								};
							};

							cam_1@1b {

								ports {

									port@0 {

										endpoint {
											remote-endpoint = <0x00>;
										};
									};
								};
							};

							cam_0@1a {

								ports {

									port@0 {

										endpoint {
											remote-endpoint = <0x00>;
										};
									};
								};
							};
						};
					};
				};
			};
		};
	};
};
